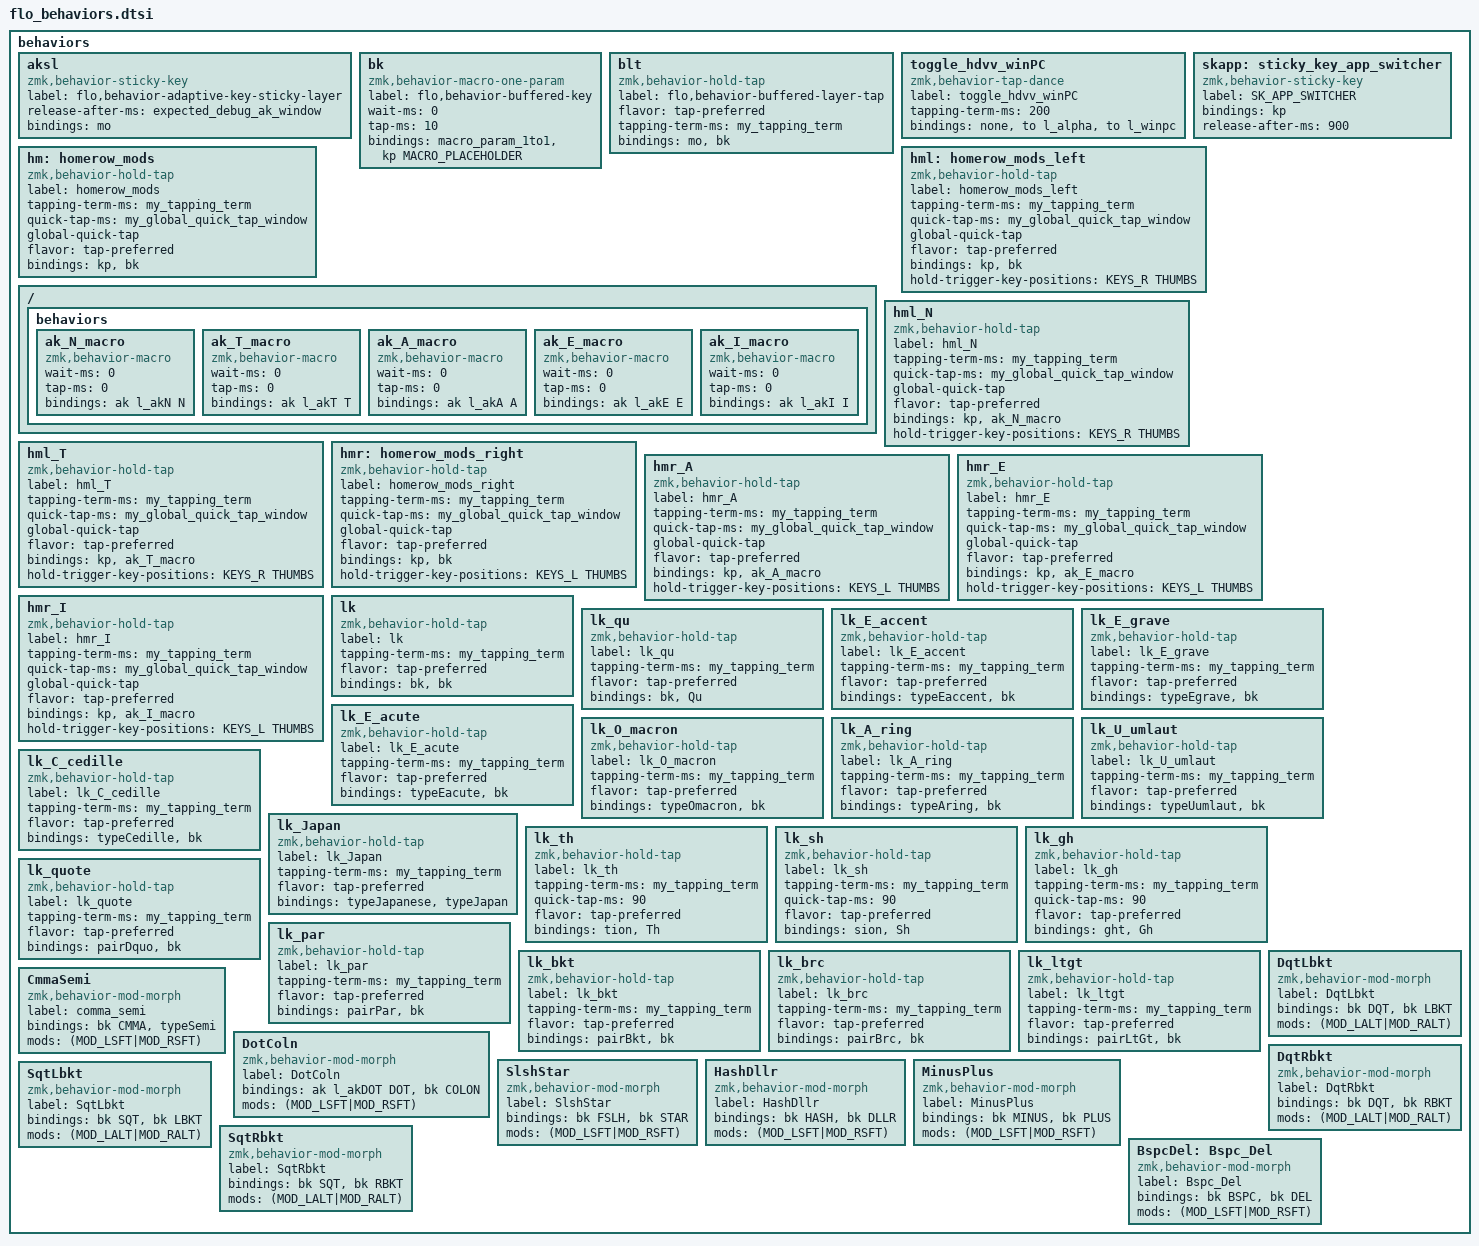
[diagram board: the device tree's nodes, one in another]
#define ak_A &ak l_akA A
#define ak_B &ak l_akB B
#define ak_C &ak l_akC C
#define ak_D &ak l_akD D
#define ak_E &ak l_akE E
#define ak_F &ak l_akF F
#define ak_G &ak l_akG G
#define ak_H &ak l_akH H
#define ak_I &ak l_akI I
#define ak_J &ak l_akJ J
#define ak_K &ak l_akK K
#define ak_L &ak l_akL L
#define ak_M &ak l_akM M
#define ak_N &ak l_akN N
#define ak_O &ak l_akO O
#define ak_P &ak l_akP P
#define ak_Q &ak l_akQ Q
#define ak_R &ak l_akR R
#define ak_S &ak l_akS S
#define ak_T &ak l_akT T
#define ak_U &ak l_akU U
#define ak_V &ak l_akV V
#define ak_W &ak l_akW W
#define ak_X &ak l_akX X
#define ak_Y &ak l_akY Y
#define ak_Z &ak l_akZ Z

behaviors {

    aksl: aksl {
        compatible = "zmk,behavior-sticky-key";
        label = "flo,behavior-adaptive-key-sticky-layer";
        #binding-cells = <1>;
        release-after-ms = <expected_debug_ak_window>;
        bindings = <&mo>;
        // We are NOT using 'quick-release', that way the ak layer won't be deactivated until
        // the next &kp releases. Which means the next ak_layer will be activated immediately!
    };

    bk: bk {
        label = "flo,behavior-buffered-key";
        compatible = "zmk,behavior-macro-one-param";
        #binding-cells = <1>;
        wait-ms = <0>;
        tap-ms = <10>;
        bindings = <&macro_param_1to1>,
                <&kp MACRO_PLACEHOLDER>;
    };


    blt: blt {
        compatible = "zmk,behavior-hold-tap";
        label = "flo,behavior-buffered-layer-tap";
        #binding-cells = <2>;
        flavor = "tap-preferred";
        tapping-term-ms = <my_tapping_term>;
        bindings = <&mo>, <&bk>;
    };


    toggle_hdvv_winPC: toggle_hdvv_winPC {
        compatible = "zmk,behavior-tap-dance";
        label = "toggle_hdvv_winPC";
        #binding-cells = <0>;
        tapping-term-ms = <200>;
        bindings = <&none>, <&to l_alpha>, <&to l_winpc>;
    };

    skapp: sticky_key_app_switcher {
        compatible = "zmk,behavior-sticky-key";
        label = "SK_APP_SWITCHER";
        #binding-cells = <1>;
        bindings = <&kp>;
        release-after-ms = <900>;
    };


    /******************** Home Row Mods **********************/
    hm: homerow_mods { // use on either hand
        compatible = "zmk,behavior-hold-tap";
        label = "homerow_mods";
        #binding-cells = <2>;
        tapping-term-ms = <my_tapping_term>;
        quick-tap-ms = <my_global_quick_tap_window>;
        global-quick-tap;
        flavor = "tap-preferred";
        bindings = <&kp>, <&bk>;
    };

    hml: homerow_mods_left { // use on left hand to mod right
        compatible = "zmk,behavior-hold-tap";
        label = "homerow_mods_left";
        #binding-cells = <2>;
        tapping-term-ms = <my_tapping_term>;
        quick-tap-ms = <my_global_quick_tap_window>;
        global-quick-tap;
        flavor = "tap-preferred";
        bindings = <&kp>, <&bk>;
        hold-trigger-key-positions = <KEYS_R THUMBS>; // right hand allowed
    };
    ZMK_MACRO(ak_N_macro, wait-ms = <0>; tap-ms = <0>; bindings = <&ak l_akN N>;)
    hml_N: hml_N {
        compatible = "zmk,behavior-hold-tap";
        label = "hml_N";
        #binding-cells = <2>;
        tapping-term-ms = <my_tapping_term>;
        quick-tap-ms = <my_global_quick_tap_window>;
        global-quick-tap;
        flavor = "tap-preferred";
        bindings = <&kp>, <&ak_N_macro>;
        hold-trigger-key-positions = <KEYS_R THUMBS>; // right hand allowed
    };
    ZMK_MACRO(ak_T_macro, wait-ms = <0>; tap-ms = <0>; bindings = <&ak l_akT T>;)
    hml_T: hml_T {
        compatible = "zmk,behavior-hold-tap";
        label = "hml_T";
        #binding-cells = <2>;
        tapping-term-ms = <my_tapping_term>;
        quick-tap-ms = <my_global_quick_tap_window>;
        global-quick-tap;
        flavor = "tap-preferred";
        bindings = <&kp>, <&ak_T_macro>;
        hold-trigger-key-positions = <KEYS_R THUMBS>; // right hand allowed
    };

    hmr: homerow_mods_right { // use on right hand to mod left
        compatible = "zmk,behavior-hold-tap";
        label = "homerow_mods_right";
        #binding-cells = <2>;
        tapping-term-ms = <my_tapping_term>;
        quick-tap-ms = <my_global_quick_tap_window>;
        global-quick-tap;
        flavor = "tap-preferred";
        bindings = <&kp>, <&bk>;
        hold-trigger-key-positions = <KEYS_L THUMBS>; // left hand allowed
    };
    ZMK_MACRO(ak_A_macro, wait-ms = <0>; tap-ms = <0>; bindings = <&ak l_akA A>;)
    hmr_A: hmr_A {
        compatible = "zmk,behavior-hold-tap";
        label = "hmr_A";
        #binding-cells = <2>;
        tapping-term-ms = <my_tapping_term>;
        quick-tap-ms = <my_global_quick_tap_window>;
        global-quick-tap;
        flavor = "tap-preferred";
        bindings = <&kp>, <&ak_A_macro>;
        hold-trigger-key-positions = <KEYS_L THUMBS>; // left hand allowed
    };
    ZMK_MACRO(ak_E_macro, wait-ms = <0>; tap-ms = <0>; bindings = <&ak l_akE E>;)
    hmr_E: hmr_E {
        compatible = "zmk,behavior-hold-tap";
        label = "hmr_E";
        #binding-cells = <2>;
        tapping-term-ms = <my_tapping_term>;
        quick-tap-ms = <my_global_quick_tap_window>;
        global-quick-tap;
        flavor = "tap-preferred";
        bindings = <&kp>, <&ak_E_macro>;
        hold-trigger-key-positions = <KEYS_L THUMBS>; // left hand allowed
    };
    ZMK_MACRO(ak_I_macro, wait-ms = <0>; tap-ms = <0>; bindings = <&ak l_akI I>;)
    hmr_I: hmr_I {
        compatible = "zmk,behavior-hold-tap";
        label = "hmr_I";
        #binding-cells = <2>;
        tapping-term-ms = <my_tapping_term>;
        quick-tap-ms = <my_global_quick_tap_window>;
        global-quick-tap;
        flavor = "tap-preferred";
        bindings = <&kp>, <&ak_I_macro>;
        hold-trigger-key-positions = <KEYS_L THUMBS>; // left hand allowed
    };





    /******************** Linger Keys **********************/
    lk: lk {
        compatible = "zmk,behavior-hold-tap";
        label = "lk";
        #binding-cells = <2>;
        tapping-term-ms = <my_tapping_term>;
        flavor = "tap-preferred";
        bindings = <&bk>, <&bk>;
    };
    lk_qu: lk_qu {
        compatible = "zmk,behavior-hold-tap";
        label = "lk_qu";
        #binding-cells = <2>;
        tapping-term-ms = <my_tapping_term>;
        flavor = "tap-preferred";
        bindings = <&bk>, <&Qu>;
    };

    lk_E_accent: lk_E_accent { // ´, é on "linger"
        compatible = "zmk,behavior-hold-tap";
        label = "lk_E_accent";
        #binding-cells = <2>;
        tapping-term-ms = <my_tapping_term>;
        flavor = "tap-preferred";
        bindings = <&typeEaccent>, <&bk>;
    };
    lk_E_grave: lk_E_grave { // `, è on "linger"
        compatible = "zmk,behavior-hold-tap";
        label = "lk_E_grave";
        #binding-cells = <2>;
        tapping-term-ms = <my_tapping_term>;
        flavor = "tap-preferred";
        bindings = <&typeEgrave>, <&bk>;
    };
    lk_E_acute: lk_E_acute { // ˆ, ê on "linger"
        compatible = "zmk,behavior-hold-tap";
        label = "lk_E_acute";
        #binding-cells = <2>;
        tapping-term-ms = <my_tapping_term>;
        flavor = "tap-preferred";
        bindings = <&typeEacute>, <&bk>;
    };
    lk_O_macron: lk_O_macron { // ¯, ō on "linger"
        compatible = "zmk,behavior-hold-tap";
        label = "lk_O_macron";
        #binding-cells = <2>;
        tapping-term-ms = <my_tapping_term>;
        flavor = "tap-preferred";
        bindings = <&typeOmacron>, <&bk>;
    };
    lk_A_ring: lk_A_ring { // ˚, å on "linger"
        compatible = "zmk,behavior-hold-tap";
        label = "lk_A_ring";
        #binding-cells = <2>;
        tapping-term-ms = <my_tapping_term>;
        flavor = "tap-preferred";
        bindings = <&typeAring>, <&bk>;
    };
    lk_U_umlaut: lk_U_umlaut { // ¨, ü on "linger"
        compatible = "zmk,behavior-hold-tap";
        label = "lk_U_umlaut";
        #binding-cells = <2>;
        tapping-term-ms = <my_tapping_term>;
        flavor = "tap-preferred";
        bindings = <&typeUumlaut>, <&bk>;
    };
    lk_C_cedille: lk_C_cedille { // ¸, ç on "linger"
        compatible = "zmk,behavior-hold-tap";
        label = "lk_C_cedille";
        #binding-cells = <2>;
        tapping-term-ms = <my_tapping_term>;
        flavor = "tap-preferred";
        bindings = <&typeCedille>, <&bk>;
    };


    lk_Japan: lk_Japan { // Japan on tap, Japanese on "linger"
        compatible = "zmk,behavior-hold-tap";
        label = "lk_Japan";
        #binding-cells = <2>;
        tapping-term-ms = <my_tapping_term>;
        flavor = "tap-preferred";
        bindings = <&typeJapanese>, <&typeJapan>;
    };
    lk_th: lk_th { // Th on tap, tion on "linger"
        compatible = "zmk,behavior-hold-tap";
        label = "lk_th";
        #binding-cells = <2>;
        tapping-term-ms = <my_tapping_term>;
        quick-tap-ms = <90>;
//            global-quick-tap;
        flavor = "tap-preferred";
        bindings = <&tion>, <&Th>;
    };
    lk_sh: lk_sh { // Sh on tap, sion on "linger"
        compatible = "zmk,behavior-hold-tap";
        label = "lk_sh";
        #binding-cells = <2>;
        tapping-term-ms = <my_tapping_term>;
        quick-tap-ms = <90>;
//            global-quick-tap;
        flavor = "tap-preferred";
        bindings = <&sion>, <&Sh>;
    };
    lk_gh: lk_gh { // Gh on tap, Ght on "linger"
        compatible = "zmk,behavior-hold-tap";
        label = "lk_gh";
        #binding-cells = <2>;
        tapping-term-ms = <my_tapping_term>;
        quick-tap-ms = <90>;
//            global-quick-tap;
        flavor = "tap-preferred";
        bindings = <&ght>, <&Gh>;
    };
    lk_quote: lk_quote { // " on tap, “” on "linger" (curly quotes)
        compatible = "zmk,behavior-hold-tap";
        label = "lk_quote";
        #binding-cells = <2>;
        tapping-term-ms = <my_tapping_term>;
        flavor = "tap-preferred";
        bindings = <&pairDquo>, <&bk>;
    };
    lk_par: lk_par { // ( on tap, () on "linger"
        compatible = "zmk,behavior-hold-tap";
        label = "lk_par";
        #binding-cells = <2>;
        tapping-term-ms = <my_tapping_term>;
        flavor = "tap-preferred";
        bindings = <&pairPar>, <&bk>;
    };
    lk_bkt: lk_bkt { // [ on tap, [] on "linger"
        compatible = "zmk,behavior-hold-tap";
        label = "lk_bkt";
        #binding-cells = <2>;
        tapping-term-ms = <my_tapping_term>;
        flavor = "tap-preferred";
        bindings = <&pairBkt>, <&bk>;
    };
    lk_brc: lk_brc { // { on tap, {} on "linger"
        compatible = "zmk,behavior-hold-tap";
        label = "lk_brc";
        #binding-cells = <2>;
        tapping-term-ms = <my_tapping_term>;
        flavor = "tap-preferred";
        bindings = <&pairBrc>, <&bk>;
    };
    lk_ltgt: lk_ltgt { // < on tap, <|> on "linger"
        compatible = "zmk,behavior-hold-tap";
        label = "lk_ltgt";
        #binding-cells = <2>;
        tapping-term-ms = <my_tapping_term>;
        flavor = "tap-preferred";
        bindings = <&pairLtGt>, <&bk>;
    };

    CmmaSemi: CmmaSemi {
        compatible = "zmk,behavior-mod-morph";
        label = "comma_semi";
        #binding-cells = <0>;
        bindings = <&bk CMMA>, <&typeSemi>;
        mods = <(MOD_LSFT|MOD_RSFT)>;
    };
    DotColn: DotColn {
        compatible = "zmk,behavior-mod-morph";
        label = "DotColn";
        #binding-cells = <0>;
        bindings = <&ak l_akDOT DOT>, <&bk COLON>;
        mods = <(MOD_LSFT|MOD_RSFT)>;
    };
    SlshStar: SlshStar {
        compatible = "zmk,behavior-mod-morph";
        label = "SlshStar";
        #binding-cells = <0>;
        bindings = <&bk FSLH>, <&bk STAR>;
        mods = <(MOD_LSFT|MOD_RSFT)>;
    };
    HashDllr: HashDllr {
        compatible = "zmk,behavior-mod-morph";
        label = "HashDllr";
        #binding-cells = <0>;
        bindings = <&bk HASH>, <&bk DLLR>;
        mods = <(MOD_LSFT|MOD_RSFT)>;
    };
    MinusPlus: MinusPlus {
        compatible = "zmk,behavior-mod-morph";
        label = "MinusPlus";
        #binding-cells = <0>;
        bindings = <&bk MINUS>, <&bk PLUS>;
        mods = <(MOD_LSFT|MOD_RSFT)>;
    };
    DqtLbkt: DqtLbkt {
        compatible = "zmk,behavior-mod-morph";
        label = "DqtLbkt";
        #binding-cells = <0>;
        bindings = <&bk DQT>, <&bk LBKT>;
        mods = <(MOD_LALT|MOD_RALT)>;
    };
    DqtRbkt: DqtRbkt {
        compatible = "zmk,behavior-mod-morph";
        label = "DqtRbkt";
        #binding-cells = <0>;
        bindings = <&bk DQT>, <&bk RBKT>;
        mods = <(MOD_LALT|MOD_RALT)>;
    };
    SqtLbkt: SqtLbkt {
        compatible = "zmk,behavior-mod-morph";
        label = "SqtLbkt";
        #binding-cells = <0>;
        bindings = <&bk SQT>, <&bk LBKT>;
        mods = <(MOD_LALT|MOD_RALT)>;
    };
    SqtRbkt: SqtRbkt {
        compatible = "zmk,behavior-mod-morph";
        label = "SqtRbkt";
        #binding-cells = <0>;
        bindings = <&bk SQT>, <&bk RBKT>;
        mods = <(MOD_LALT|MOD_RALT)>;
    };
    BspcDel: Bspc_Del {
        compatible = "zmk,behavior-mod-morph";
        label = "Bspc_Del";
        #binding-cells = <0>;
        bindings = <&bk BSPC>, <&bk DEL>;
        mods = <(MOD_LSFT|MOD_RSFT)>;
    };
};
